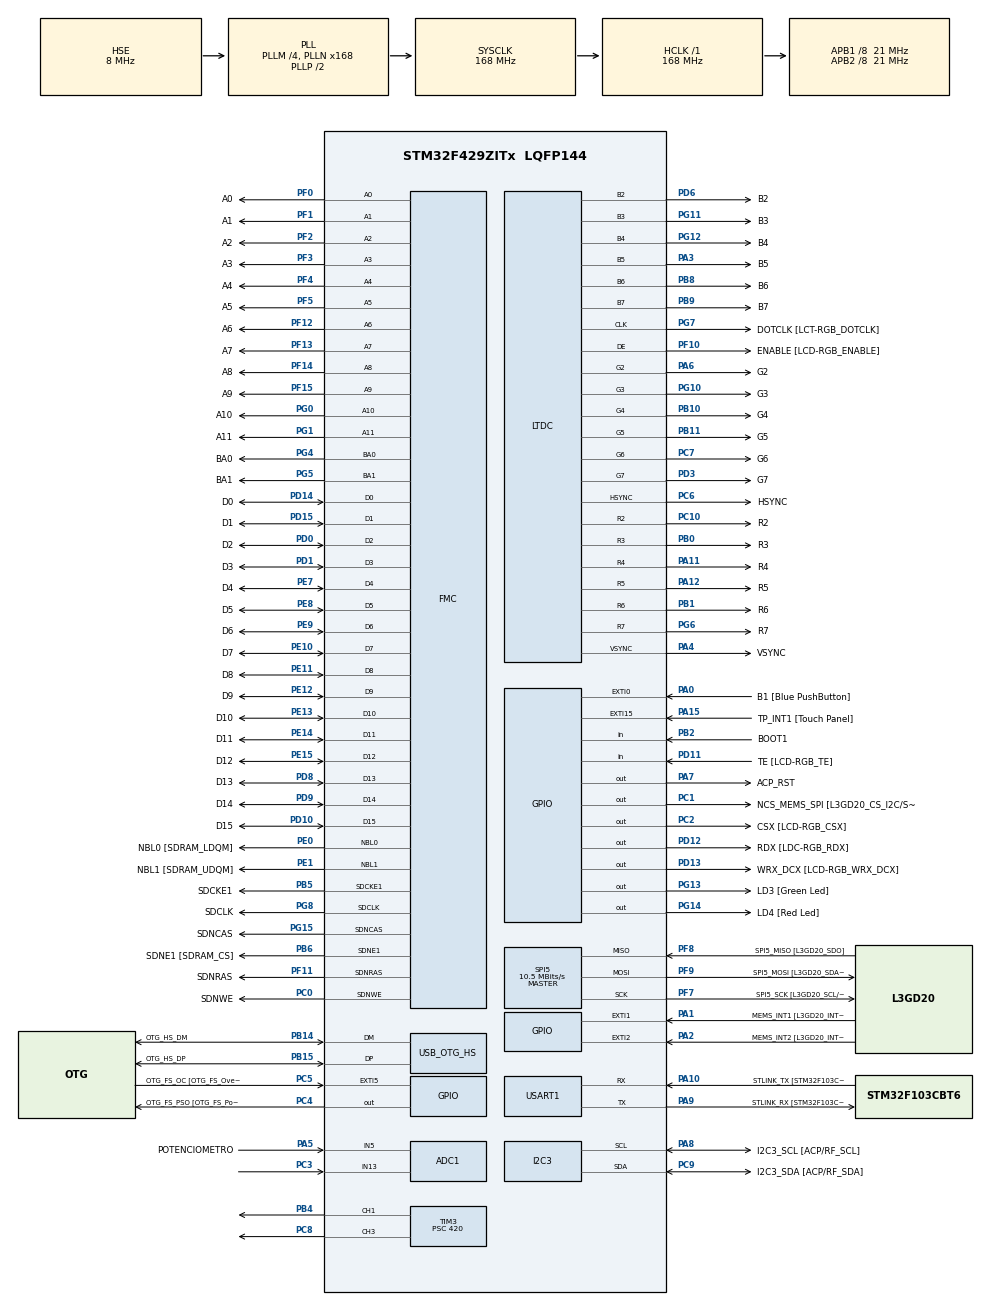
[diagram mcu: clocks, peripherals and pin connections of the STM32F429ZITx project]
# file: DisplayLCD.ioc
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ADC1.Channel-3\#ChannelRegularConversion=ADC_CHANNEL_5
ADC1.Channel-4\#ChannelRegularConversion=ADC_CHANNEL_5
ADC1.NbrOfConversion=2
ADC1.NbrOfConversionFlag=1
ADC1.Rank-3\#ChannelRegularConversion=1
ADC1.Rank-4\#ChannelRegularConversion=2
ADC1.SamplingTime-3\#ChannelRegularConversion=ADC_SAMPLETIME_144CYCLES
ADC1.SamplingTime-4\#ChannelRegularConversion=ADC_SAMPLETIME_144CYCLES
ADC1.ScanConvMode=ENABLE
ADC1.master=1
DMA2D.ColorMode=DMA2D_OUTPUT_RGB565
FATFS._MAX_SS=4096
LTDC.ActiveH=240
LTDC.ActiveW=320
Mcu.Family=STM32F4
Mcu.Name=STM32F429ZITx
Mcu.Package=LQFP144
NVIC.OTG_HS_IRQn=true\:0\:0\:false\:false\:true\:false
NVIC.PriorityGroup=NVIC_PRIORITYGROUP_0
NVIC.USART1_IRQn=true\:0\:0\:false\:false\:true\:true
PA0/WKUP.GPIO_Label=B1 [Blue PushButton]
PA0/WKUP.GPIO_ModeDefaultEXTI=GPIO_MODE_EVT_RISING
PA0/WKUP.GPIO_PuPd=GPIO_NOPULL
PA0/WKUP.Signal=GPXTI0
PA1.GPIO_Label=MEMS_INT1 [L3GD20_INT1]
PA1.GPIO_ModeDefaultEXTI=GPIO_MODE_EVT_RISING
PA1.GPIO_PuPd=GPIO_NOPULL
PA1.Signal=GPXTI1
PA10.GPIO_Label=STLINK_TX [STM32F103CBT6_PA2]
PA10.Mode=Asynchronous
PA10.Signal=USART1_RX
PA11.GPIO_Label=R4
PA11.GPIO_Mode=GPIO_MODE_AF_PP
PA11.GPIO_PuPd=GPIO_NOPULL
PA11.GPIO_Speed=GPIO_SPEED_FREQ_LOW
PA11.Mode=RGB666
PA11.Signal=LTDC_R4
PA12.GPIO_Label=R5
PA12.GPIO_Mode=GPIO_MODE_AF_PP
PA12.GPIO_PuPd=GPIO_NOPULL
PA12.GPIO_Speed=GPIO_SPEED_FREQ_LOW
PA12.Mode=RGB666
PA12.Signal=LTDC_R5
PA13.GPIO_Label=SWDIO
PA13.Mode=Serial_Wire
PA13.Signal=SYS_JTMS-SWDIO
PA14.GPIO_Label=SWCLK
PA14.Mode=Serial_Wire
PA14.Signal=SYS_JTCK-SWCLK
PA15.GPIO_Label=TP_INT1 [Touch Panel]
PA15.GPIO_ModeDefaultEXTI=GPIO_MODE_EVT_RISING
PA15.GPIO_PuPd=GPIO_NOPULL
PA15.Signal=GPXTI15
PA2.GPIO_Label=MEMS_INT2 [L3GD20_INT2]
PA2.GPIO_ModeDefaultEXTI=GPIO_MODE_EVT_RISING
PA2.GPIO_PuPd=GPIO_NOPULL
PA2.Signal=GPXTI2
PA3.GPIO_Label=B5
PA3.GPIO_Mode=GPIO_MODE_AF_PP
PA3.GPIO_PuPd=GPIO_NOPULL
PA3.GPIO_Speed=GPIO_SPEED_FREQ_LOW
PA3.Mode=RGB666
PA3.Signal=LTDC_B5
PA4.GPIO_Label=VSYNC
PA4.GPIO_Mode=GPIO_MODE_AF_PP
PA4.GPIO_PuPd=GPIO_NOPULL
PA4.GPIO_Speed=GPIO_SPEED_FREQ_LOW
PA4.Mode=RGB666
PA4.Signal=LTDC_VSYNC
PA5.GPIO_Label=POTENCIOMETRO
PA5.Signal=ADCx_IN5
PA6.GPIO_Label=G2
PA6.GPIO_Mode=GPIO_MODE_AF_PP
PA6.GPIO_PuPd=GPIO_NOPULL
PA6.GPIO_Speed=GPIO_SPEED_FREQ_LOW
PA6.Mode=RGB666
PA6.Signal=LTDC_G2
PA7.GPIO_Label=ACP_RST
PA7.GPIO_Mode=GPIO_MODE_OUTPUT_PP
PA7.GPIO_PuPd=GPIO_NOPULL
PA7.GPIO_Speed=GPIO_SPEED_FREQ_LOW
PA7.Signal=GPIO_Output
PA8.GPIO_Label=I2C3_SCL [ACP/RF_SCL]
PA8.GPIO_Mode=GPIO_MODE_AF_OD
PA8.GPIO_PuPd=GPIO_NOPULL
PA8.GPIO_Speed=GPIO_SPEED_FREQ_LOW
PA8.Mode=I2C
PA8.Signal=I2C3_SCL
PA9.GPIO_Label=STLINK_RX [STM32F103CBT6_PA3]
PA9.Mode=Asynchronous
PA9.Signal=USART1_TX
PB0.GPIO_Label=R3
PB0.GPIO_Mode=GPIO_MODE_AF_PP
PB0.GPIO_PuPd=GPIO_NOPULL
PB0.GPIO_Speed=GPIO_SPEED_FREQ_LOW
PB0.Mode=RGB666
PB0.Signal=LTDC_R3
PB1.GPIO_Label=R6
PB1.GPIO_Mode=GPIO_MODE_AF_PP
PB1.GPIO_PuPd=GPIO_NOPULL
PB1.GPIO_Speed=GPIO_SPEED_FREQ_LOW
PB1.Mode=RGB666
PB1.Signal=LTDC_R6
PB10.GPIO_Label=G4
PB10.GPIO_Mode=GPIO_MODE_AF_PP
PB10.GPIO_PuPd=GPIO_NOPULL
PB10.GPIO_Speed=GPIO_SPEED_FREQ_LOW
PB10.Mode=RGB666
PB10.Signal=LTDC_G4
PB11.GPIO_Label=G5
PB11.GPIO_Mode=GPIO_MODE_AF_PP
PB11.GPIO_PuPd=GPIO_NOPULL
PB11.GPIO_Speed=GPIO_SPEED_FREQ_LOW
PB11.Mode=RGB666
PB11.Signal=LTDC_G5
PB12.GPIO_Label=OTG_HS_ID
PB12.GPIO_Mode=GPIO_MODE_AF_PP
PB12.GPIO_PuPd=GPIO_NOPULL
PB12.GPIO_Speed=GPIO_SPEED_FREQ_LOW
PB12.Signal=USB_OTG_HS_ID
PB13.GPIO_Label=VBUS_HS
PB13.GPIO_Mode=GPIO_MODE_INPUT
PB13.GPIO_PuPd=GPIO_NOPULL
PB13.Signal=USB_OTG_HS_VBUS
PB14.GPIO_Label=OTG_HS_DM
PB14.GPIO_Mode=GPIO_MODE_AF_PP
PB14.GPIO_PuPd=GPIO_NOPULL
PB14.GPIO_Speed=GPIO_SPEED_FREQ_LOW
PB14.Mode=Host_FS
PB14.Signal=USB_OTG_HS_DM
PB15.GPIO_Label=OTG_HS_DP
PB15.GPIO_Mode=GPIO_MODE_AF_PP
PB15.GPIO_PuPd=GPIO_NOPULL
PB15.GPIO_Speed=GPIO_SPEED_FREQ_LOW
PB15.Mode=Host_FS
PB15.Signal=USB_OTG_HS_DP
PB2/BOOT1.GPIO_Label=BOOT1
PB2/BOOT1.GPIO_Mode=GPIO_MODE_INPUT
PB2/BOOT1.GPIO_PuPd=GPIO_NOPULL
PB2/BOOT1.Signal=GPIO_Input
PB4.Signal=S_TIM3_CH1
PB5.GPIO_Label=SDCKE1
PB5.GPIO_Mode=GPIO_MODE_AF_PP
PB5.GPIO_PuPd=GPIO_NOPULL
PB5.GPIO_Speed=GPIO_SPEED_FREQ_VERY_HIGH
PB5.Mode=SdramChipSelect2_1
PB5.Signal=FMC_SDCKE1
PB6.GPIO_Label=SDNE1 [SDRAM_CS]
PB6.GPIO_Mode=GPIO_MODE_AF_PP
PB6.GPIO_PuPd=GPIO_NOPULL
PB6.GPIO_Speed=GPIO_SPEED_FREQ_VERY_HIGH
PB6.Mode=SdramChipSelect2_1
PB6.Signal=FMC_SDNE1
PB8.GPIO_Label=B6
PB8.GPIO_Mode=GPIO_MODE_AF_PP
PB8.GPIO_PuPd=GPIO_NOPULL
PB8.GPIO_Speed=GPIO_SPEED_FREQ_LOW
PB8.Mode=RGB666
PB8.Signal=LTDC_B6
PB9.GPIO_Label=B7
PB9.GPIO_Mode=GPIO_MODE_AF_PP
PB9.GPIO_PuPd=GPIO_NOPULL
PB9.GPIO_Speed=GPIO_SPEED_FREQ_LOW
PB9.Mode=RGB666
PB9.Signal=LTDC_B7
PC0.GPIO_Label=SDNWE
PC0.GPIO_Mode=GPIO_MODE_AF_PP
PC0.GPIO_PuPd=GPIO_NOPULL
PC0.GPIO_Speed=GPIO_SPEED_FREQ_VERY_HIGH
PC0.Signal=FMC_SDNWE
PC1.GPIO_Label=NCS_MEMS_SPI [L3GD20_CS_I2C/SPI]
PC1.GPIO_Mode=GPIO_MODE_OUTPUT_PP
PC1.GPIO_PuPd=GPIO_NOPULL
PC1.GPIO_Speed=GPIO_SPEED_FREQ_LOW
PC1.Signal=GPIO_Output
PC10.GPIO_Label=R2
PC10.GPIO_Mode=GPIO_MODE_AF_PP
PC10.GPIO_PuPd=GPIO_NOPULL
PC10.GPIO_Speed=GPIO_SPEED_FREQ_LOW
PC10.Mode=RGB666
PC10.Signal=LTDC_R2
PC14/OSC32_IN.GPIO_Label=PC14-OSC32_IN
PC14/OSC32_IN.Signal=RCC_OSC32_IN
PC15/OSC32_OUT.GPIO_Label=PC15-OSC32_OUT
PC15/OSC32_OUT.Signal=RCC_OSC32_OUT
PC2.GPIO_Label=CSX [LCD-RGB_CSX]
PC2.GPIO_Mode=GPIO_MODE_OUTPUT_PP
PC2.GPIO_PuPd=GPIO_NOPULL
PC2.GPIO_Speed=GPIO_SPEED_FREQ_LOW
PC2.Signal=GPIO_Output
PC3.Signal=ADCx_IN13
PC4.GPIO_Label=OTG_FS_PSO [OTG_FS_PowerSwitchOn]
PC4.GPIO_Mode=GPIO_MODE_OUTPUT_PP
PC4.GPIO_PuPd=GPIO_NOPULL
PC4.GPIO_Speed=GPIO_SPEED_FREQ_LOW
PC4.Signal=GPIO_Output
PC5.GPIO_Label=OTG_FS_OC [OTG_FS_OverCurrent]
PC5.GPIO_ModeDefaultEXTI=GPIO_MODE_EVT_RISING
PC5.Signal=GPXTI5
PC6.GPIO_Label=HSYNC
PC6.GPIO_Mode=GPIO_MODE_AF_PP
PC6.GPIO_PuPd=GPIO_NOPULL
PC6.GPIO_Speed=GPIO_SPEED_FREQ_LOW
PC6.Mode=RGB666
PC6.Signal=LTDC_HSYNC
PC7.GPIO_Label=G6
PC7.GPIO_Mode=GPIO_MODE_AF_PP
PC7.GPIO_PuPd=GPIO_NOPULL
PC7.GPIO_Speed=GPIO_SPEED_FREQ_LOW
PC7.Mode=RGB666
PC7.Signal=LTDC_G6
PC8.Signal=S_TIM3_CH3
PC9.GPIO_Label=I2C3_SDA [ACP/RF_SDA]
PC9.GPIO_Mode=GPIO_MODE_AF_OD
PC9.GPIO_PuPd=GPIO_NOPULL
PC9.GPIO_Speed=GPIO_SPEED_FREQ_LOW
PC9.Mode=I2C
PC9.Signal=I2C3_SDA
PD0.GPIO_Label=D2
PD0.GPIO_Mode=GPIO_MODE_AF_PP
PD0.GPIO_PuPd=GPIO_NOPULL
PD0.GPIO_Speed=GPIO_SPEED_FREQ_VERY_HIGH
PD0.Signal=FMC_D2_DA2
PD1.GPIO_Label=D3
PD1.GPIO_Mode=GPIO_MODE_AF_PP
PD1.GPIO_PuPd=GPIO_NOPULL
PD1.GPIO_Speed=GPIO_SPEED_FREQ_VERY_HIGH
PD1.Signal=FMC_D3_DA3
PD10.GPIO_Label=D15
PD10.GPIO_Mode=GPIO_MODE_AF_PP
PD10.GPIO_PuPd=GPIO_NOPULL
PD10.GPIO_Speed=GPIO_SPEED_FREQ_VERY_HIGH
PD10.Signal=FMC_D15_DA15
PD11.GPIO_Label=TE [LCD-RGB_TE]
PD11.GPIO_Mode=GPIO_MODE_INPUT
PD11.GPIO_PuPd=GPIO_NOPULL
PD11.Signal=GPIO_Input
PD12.GPIO_Label=RDX [LDC-RGB_RDX]
PD12.GPIO_Mode=GPIO_MODE_OUTPUT_PP
PD12.GPIO_PuPd=GPIO_NOPULL
PD12.GPIO_Speed=GPIO_SPEED_FREQ_LOW
PD12.Signal=GPIO_Output
PD13.GPIO_Label=WRX_DCX [LCD-RGB_WRX_DCX]
PD13.GPIO_Mode=GPIO_MODE_OUTPUT_PP
PD13.GPIO_PuPd=GPIO_NOPULL
PD13.GPIO_Speed=GPIO_SPEED_FREQ_LOW
PD13.Signal=GPIO_Output
PD14.GPIO_Label=D0
PD14.GPIO_Mode=GPIO_MODE_AF_PP
PD14.GPIO_PuPd=GPIO_NOPULL
PD14.GPIO_Speed=GPIO_SPEED_FREQ_VERY_HIGH
PD14.Signal=FMC_D0_DA0
PD15.GPIO_Label=D1
PD15.GPIO_Mode=GPIO_MODE_AF_PP
PD15.GPIO_PuPd=GPIO_NOPULL
PD15.GPIO_Speed=GPIO_SPEED_FREQ_VERY_HIGH
PD15.Signal=FMC_D1_DA1
PD3.GPIO_Label=G7
PD3.GPIO_Mode=GPIO_MODE_AF_PP
PD3.GPIO_PuPd=GPIO_NOPULL
PD3.GPIO_Speed=GPIO_SPEED_FREQ_LOW
PD3.Mode=RGB666
PD3.Signal=LTDC_G7
PD6.GPIO_Label=B2
PD6.GPIO_Mode=GPIO_MODE_AF_PP
PD6.GPIO_PuPd=GPIO_NOPULL
PD6.GPIO_Speed=GPIO_SPEED_FREQ_LOW
PD6.Mode=RGB666
PD6.Signal=LTDC_B2
PD8.GPIO_Label=D13
PD8.GPIO_Mode=GPIO_MODE_AF_PP
PD8.GPIO_PuPd=GPIO_NOPULL
PD8.GPIO_Speed=GPIO_SPEED_FREQ_VERY_HIGH
PD8.Signal=FMC_D13_DA13
PD9.GPIO_Label=D14
PD9.GPIO_Mode=GPIO_MODE_AF_PP
PD9.GPIO_PuPd=GPIO_NOPULL
PD9.GPIO_Speed=GPIO_SPEED_FREQ_VERY_HIGH
PD9.Signal=FMC_D14_DA14
PE0.GPIO_Label=NBL0 [SDRAM_LDQM]
PE0.GPIO_Mode=GPIO_MODE_AF_PP
PE0.GPIO_PuPd=GPIO_NOPULL
PE0.GPIO_Speed=GPIO_SPEED_FREQ_VERY_HIGH
PE0.Signal=FMC_NBL0
PE1.GPIO_Label=NBL1 [SDRAM_UDQM]
PE1.GPIO_Mode=GPIO_MODE_AF_PP
PE1.GPIO_PuPd=GPIO_NOPULL
PE1.GPIO_Speed=GPIO_SPEED_FREQ_VERY_HIGH
PE1.Signal=FMC_NBL1
PE10.GPIO_Label=D7
PE10.GPIO_Mode=GPIO_MODE_AF_PP
PE10.GPIO_PuPd=GPIO_NOPULL
PE10.GPIO_Speed=GPIO_SPEED_FREQ_VERY_HIGH
PE10.Signal=FMC_D7_DA7
PE11.GPIO_Label=D8
PE11.GPIO_Mode=GPIO_MODE_AF_PP
PE11.GPIO_PuPd=GPIO_NOPULL
PE11.GPIO_Speed=GPIO_SPEED_FREQ_VERY_HIGH
PE11.Signal=FMC_D8_DA8
PE12.GPIO_Label=D9
PE12.GPIO_Mode=GPIO_MODE_AF_PP
PE12.GPIO_PuPd=GPIO_NOPULL
PE12.GPIO_Speed=GPIO_SPEED_FREQ_VERY_HIGH
PE12.Signal=FMC_D9_DA9
PE13.GPIO_Label=D10
PE13.GPIO_Mode=GPIO_MODE_AF_PP
PE13.GPIO_PuPd=GPIO_NOPULL
PE13.GPIO_Speed=GPIO_SPEED_FREQ_VERY_HIGH
PE13.Signal=FMC_D10_DA10
PE14.GPIO_Label=D11
PE14.GPIO_Mode=GPIO_MODE_AF_PP
PE14.GPIO_PuPd=GPIO_NOPULL
PE14.GPIO_Speed=GPIO_SPEED_FREQ_VERY_HIGH
PE14.Signal=FMC_D11_DA11
PE15.GPIO_Label=D12
PE15.GPIO_Mode=GPIO_MODE_AF_PP
PE15.GPIO_PuPd=GPIO_NOPULL
PE15.GPIO_Speed=GPIO_SPEED_FREQ_VERY_HIGH
PE15.Signal=FMC_D12_DA12
PE7.GPIO_Label=D4
PE7.GPIO_Mode=GPIO_MODE_AF_PP
PE7.GPIO_PuPd=GPIO_NOPULL
PE7.GPIO_Speed=GPIO_SPEED_FREQ_VERY_HIGH
PE7.Signal=FMC_D4_DA4
PE8.GPIO_Label=D5
PE8.GPIO_Mode=GPIO_MODE_AF_PP
PE8.GPIO_PuPd=GPIO_NOPULL
PE8.GPIO_Speed=GPIO_SPEED_FREQ_VERY_HIGH
PE8.Signal=FMC_D5_DA5
PE9.GPIO_Label=D6
PE9.GPIO_Mode=GPIO_MODE_AF_PP
PE9.GPIO_PuPd=GPIO_NOPULL
PE9.GPIO_Speed=GPIO_SPEED_FREQ_VERY_HIGH
PE9.Signal=FMC_D6_DA6
PF0.GPIO_Label=A0
PF0.GPIO_Mode=GPIO_MODE_AF_PP
PF0.GPIO_PuPd=GPIO_NOPULL
PF0.GPIO_Speed=GPIO_SPEED_FREQ_VERY_HIGH
PF0.Signal=FMC_A0
PF1.GPIO_Label=A1
PF1.GPIO_Mode=GPIO_MODE_AF_PP
PF1.GPIO_PuPd=GPIO_NOPULL
PF1.GPIO_Speed=GPIO_SPEED_FREQ_VERY_HIGH
PF1.Signal=FMC_A1
PF10.GPIO_Label=ENABLE [LCD-RGB_ENABLE]
PF10.GPIO_Mode=GPIO_MODE_AF_PP
PF10.GPIO_PuPd=GPIO_NOPULL
PF10.GPIO_Speed=GPIO_SPEED_FREQ_LOW
PF10.Mode=RGB666
PF10.Signal=LTDC_DE
PF11.GPIO_Label=SDNRAS
PF11.GPIO_Mode=GPIO_MODE_AF_PP
PF11.GPIO_PuPd=GPIO_NOPULL
PF11.GPIO_Speed=GPIO_SPEED_FREQ_VERY_HIGH
PF11.Signal=FMC_SDNRAS
PF12.GPIO_Label=A6
PF12.GPIO_Mode=GPIO_MODE_AF_PP
PF12.GPIO_PuPd=GPIO_NOPULL
PF12.GPIO_Speed=GPIO_SPEED_FREQ_VERY_HIGH
PF12.Signal=FMC_A6
PF13.GPIO_Label=A7
PF13.GPIO_Mode=GPIO_MODE_AF_PP
PF13.GPIO_PuPd=GPIO_NOPULL
PF13.GPIO_Speed=GPIO_SPEED_FREQ_VERY_HIGH
PF13.Signal=FMC_A7
PF14.GPIO_Label=A8
PF14.GPIO_Mode=GPIO_MODE_AF_PP
PF14.GPIO_PuPd=GPIO_NOPULL
PF14.GPIO_Speed=GPIO_SPEED_FREQ_VERY_HIGH
PF14.Signal=FMC_A8
PF15.GPIO_Label=A9
PF15.GPIO_Mode=GPIO_MODE_AF_PP
PF15.GPIO_PuPd=GPIO_NOPULL
PF15.GPIO_Speed=GPIO_SPEED_FREQ_VERY_HIGH
PF15.Signal=FMC_A9
PF2.GPIO_Label=A2
PF2.GPIO_Mode=GPIO_MODE_AF_PP
PF2.GPIO_PuPd=GPIO_NOPULL
PF2.GPIO_Speed=GPIO_SPEED_FREQ_VERY_HIGH
PF2.Signal=FMC_A2
PF3.GPIO_Label=A3
PF3.GPIO_Mode=GPIO_MODE_AF_PP
PF3.GPIO_PuPd=GPIO_NOPULL
PF3.GPIO_Speed=GPIO_SPEED_FREQ_VERY_HIGH
PF3.Signal=FMC_A3
PF4.GPIO_Label=A4
PF4.GPIO_Mode=GPIO_MODE_AF_PP
PF4.GPIO_PuPd=GPIO_NOPULL
PF4.GPIO_Speed=GPIO_SPEED_FREQ_VERY_HIGH
PF4.Signal=FMC_A4
PF5.GPIO_Label=A5
PF5.GPIO_Mode=GPIO_MODE_AF_PP
PF5.GPIO_PuPd=GPIO_NOPULL
PF5.GPIO_Speed=GPIO_SPEED_FREQ_VERY_HIGH
PF5.Signal=FMC_A5
PF7.GPIO_Label=SPI5_SCK [L3GD20_SCL/SPC]
PF7.GPIO_Mode=GPIO_MODE_AF_PP
PF7.GPIO_PuPd=GPIO_NOPULL
PF7.GPIO_Speed=GPIO_SPEED_FREQ_LOW
PF7.Mode=Full_Duplex_Master
PF7.Signal=SPI5_SCK
PF8.GPIO_Label=SPI5_MISO [L3GD20_SDO]
PF8.GPIO_Mode=GPIO_MODE_AF_PP
PF8.GPIO_PuPd=GPIO_NOPULL
PF8.GPIO_Speed=GPIO_SPEED_FREQ_LOW
PF8.Mode=Full_Duplex_Master
PF8.Signal=SPI5_MISO
PF9.GPIO_Label=SPI5_MOSI [L3GD20_SDA/SDI/SDO]
PF9.GPIO_Mode=GPIO_MODE_AF_PP
PF9.GPIO_PuPd=GPIO_NOPULL
PF9.GPIO_Speed=GPIO_SPEED_FREQ_LOW
PF9.Mode=Full_Duplex_Master
PF9.Signal=SPI5_MOSI
PG0.GPIO_Label=A10
PG0.GPIO_Mode=GPIO_MODE_AF_PP
PG0.GPIO_PuPd=GPIO_NOPULL
PG0.GPIO_Speed=GPIO_SPEED_FREQ_VERY_HIGH
PG0.Signal=FMC_A10
PG1.GPIO_Label=A11
PG1.GPIO_Mode=GPIO_MODE_AF_PP
PG1.GPIO_PuPd=GPIO_NOPULL
PG1.GPIO_Speed=GPIO_SPEED_FREQ_VERY_HIGH
PG1.Signal=FMC_A11
PG10.GPIO_Label=G3
PG10.GPIO_Mode=GPIO_MODE_AF_PP
PG10.GPIO_PuPd=GPIO_NOPULL
PG10.GPIO_Speed=GPIO_SPEED_FREQ_LOW
PG10.Mode=RGB666
PG10.Signal=LTDC_G3
PG11.GPIO_Label=B3
PG11.GPIO_Mode=GPIO_MODE_AF_PP
PG11.GPIO_PuPd=GPIO_NOPULL
PG11.GPIO_Speed=GPIO_SPEED_FREQ_LOW
PG11.Mode=RGB666
PG11.Signal=LTDC_B3
PG12.GPIO_Label=B4
PG12.GPIO_Mode=GPIO_MODE_AF_PP
PG12.GPIO_PuPd=GPIO_NOPULL
PG12.GPIO_Speed=GPIO_SPEED_FREQ_LOW
PG12.Mode=RGB666
PG12.Signal=LTDC_B4
PG13.GPIO_Label=LD3 [Green Led]
PG13.GPIO_Mode=GPIO_MODE_OUTPUT_PP
PG13.GPIO_PuPd=GPIO_NOPULL
PG13.GPIO_Speed=GPIO_SPEED_FREQ_LOW
PG13.Signal=GPIO_Output
PG14.GPIO_Label=LD4 [Red Led]
PG14.GPIO_Mode=GPIO_MODE_OUTPUT_PP
PG14.GPIO_PuPd=GPIO_NOPULL
PG14.GPIO_Speed=GPIO_SPEED_FREQ_LOW
PG14.Signal=GPIO_Output
PG15.GPIO_Label=SDNCAS
PG15.GPIO_Mode=GPIO_MODE_AF_PP
PG15.GPIO_PuPd=GPIO_NOPULL
PG15.GPIO_Speed=GPIO_SPEED_FREQ_VERY_HIGH
PG15.Signal=FMC_SDNCAS
PG4.GPIO_Label=BA0
PG4.GPIO_Mode=GPIO_MODE_AF_PP
PG4.GPIO_PuPd=GPIO_NOPULL
PG4.GPIO_Speed=GPIO_SPEED_FREQ_VERY_HIGH
PG4.Signal=FMC_A14_BA0
PG5.GPIO_Label=BA1
PG5.GPIO_Mode=GPIO_MODE_AF_PP
PG5.GPIO_PuPd=GPIO_NOPULL
PG5.GPIO_Speed=GPIO_SPEED_FREQ_VERY_HIGH
PG5.Signal=FMC_A15_BA1
PG6.GPIO_Label=R7
PG6.GPIO_Mode=GPIO_MODE_AF_PP
PG6.GPIO_PuPd=GPIO_NOPULL
PG6.GPIO_Speed=GPIO_SPEED_FREQ_LOW
PG6.Mode=RGB666
PG6.Signal=LTDC_R7
PG7.GPIO_Label=DOTCLK [LCT-RGB_DOTCLK]
PG7.GPIO_Mode=GPIO_MODE_AF_PP
PG7.GPIO_PuPd=GPIO_NOPULL
PG7.GPIO_Speed=GPIO_SPEED_FREQ_LOW
PG7.Mode=RGB666
PG7.Signal=LTDC_CLK
PG8.GPIO_Label=SDCLK
PG8.GPIO_Mode=GPIO_MODE_AF_PP
PG8.GPIO_PuPd=GPIO_NOPULL
PG8.GPIO_Speed=GPIO_SPEED_FREQ_VERY_HIGH
PG8.Signal=FMC_SDCLK
PH0/OSC_IN.GPIO_Label=PH0-OSC_IN
PH0/OSC_IN.Mode=HSE-External-Oscillator
PH0/OSC_IN.Signal=RCC_OSC_IN
PH1/OSC_OUT.GPIO_Label=PH1-OSC_OUT
PH1/OSC_OUT.Mode=HSE-External-Oscillator
PH1/OSC_OUT.Signal=RCC_OSC_OUT
ProjectManager.HeapSize=0x200
ProjectManager.StackSize=0x400
ProjectManager.TargetToolchain=MDK-ARM V5
RCC.48MHZClocksFreq_Value=48000000
RCC.AHBFreq_Value=168000000
RCC.APB1CLKDivider=RCC_HCLK_DIV8
RCC.APB1Freq_Value=21000000
RCC.APB1TimFreq_Value=42000000
RCC.APB2CLKDivider=RCC_HCLK_DIV8
RCC.APB2Freq_Value=21000000
RCC.APB2TimFreq_Value=42000000
RCC.CortexFreq_Value=168000000
RCC.HCLKFreq_Value=168000000
RCC.HSE_VALUE=8000000
RCC.HSI_VALUE=16000000
RCC.LSE_VALUE=32768
RCC.PLLM=4
RCC.PLLN=168
RCC.PLLQ=7
RCC.PLLSAIN=216
RCC.SYSCLKFreq_VALUE=168000000
RCC.SYSCLKSource=RCC_SYSCLKSOURCE_PLLCLK
RCC.VCOOutputFreq_Value=336000000
RTC.Format=RTC_FORMAT_BIN
SH.ADCx_IN13.0=ADC1_IN13,IN13
SH.ADCx_IN5.0=ADC1_IN5,IN5
SH.FMC_A0.0=FMC_A0,12b-sda1
SH.FMC_A1.0=FMC_A1,12b-sda1
SH.FMC_A10.0=FMC_A10,12b-sda1
SH.FMC_A11.0=FMC_A11,12b-sda1
SH.FMC_A14_BA0.0=FMC_BA0,FourSdramBanks1
SH.FMC_A15_BA1.0=FMC_BA1,FourSdramBanks1
SH.FMC_A2.0=FMC_A2,12b-sda1
SH.FMC_A3.0=FMC_A3,12b-sda1
SH.FMC_A4.0=FMC_A4,12b-sda1
SH.FMC_A5.0=FMC_A5,12b-sda1
SH.FMC_A6.0=FMC_A6,12b-sda1
SH.FMC_A7.0=FMC_A7,12b-sda1
SH.FMC_A8.0=FMC_A8,12b-sda1
SH.FMC_A9.0=FMC_A9,12b-sda1
SH.FMC_D0_DA0.0=FMC_D0,sd-16b-d1
SH.FMC_D10_DA10.0=FMC_D10,sd-16b-d1
SH.FMC_D11_DA11.0=FMC_D11,sd-16b-d1
SH.FMC_D12_DA12.0=FMC_D12,sd-16b-d1
SH.FMC_D13_DA13.0=FMC_D13,sd-16b-d1
SH.FMC_D14_DA14.0=FMC_D14,sd-16b-d1
SH.FMC_D15_DA15.0=FMC_D15,sd-16b-d1
SH.FMC_D1_DA1.0=FMC_D1,sd-16b-d1
SH.FMC_D2_DA2.0=FMC_D2,sd-16b-d1
SH.FMC_D3_DA3.0=FMC_D3,sd-16b-d1
SH.FMC_D4_DA4.0=FMC_D4,sd-16b-d1
SH.FMC_D5_DA5.0=FMC_D5,sd-16b-d1
SH.FMC_D6_DA6.0=FMC_D6,sd-16b-d1
SH.FMC_D7_DA7.0=FMC_D7,sd-16b-d1
SH.FMC_D8_DA8.0=FMC_D8,sd-16b-d1
SH.FMC_D9_DA9.0=FMC_D9,sd-16b-d1
SH.FMC_NBL0.0=FMC_NBL0,Sd2ByteEnable1
SH.FMC_NBL1.0=FMC_NBL1,Sd2ByteEnable1
SH.FMC_SDCLK.0=FMC_SDCLK,12b-sda1
SH.FMC_SDNCAS.0=FMC_SDNCAS,12b-sda1
SH.FMC_SDNRAS.0=FMC_SDNRAS,12b-sda1
SH.FMC_SDNWE.0=FMC_SDNWE,12b-sda1
SH.S_TIM3_CH1.0=TIM3_CH1,PWM Generation1 CH1
SH.S_TIM3_CH3.0=TIM3_CH3,PWM Generation3 CH3
SPI5.CalculateBaudRate=10.5 MBits/s
SPI5.Direction=SPI_DIRECTION_2LINES
SPI5.Mode=SPI_MODE_MASTER
SPI5.VirtualType=VM_MASTER
TIM2.Prescaler=420
TIM3.Channel-PWM\ Generation1\ CH1=TIM_CHANNEL_1
TIM3.Channel-PWM\ Generation3\ CH3=TIM_CHANNEL_3
TIM3.Period=99
TIM3.Prescaler=420
USART1.VirtualMode=VM_ASYNC
USB_HOST.BSP.number=1
USB_HOST.USBH_HandleTypeDef-MSC_HS=hUsbHostHS
USB_HOST.VirtualModeHS=Msc
USB_HOST0.BSP.STBoard=false
USB_HOST0.BSP.api=Unknown
USB_HOST0.BSP.i2caddr=0
USB_HOST0.BSP.instance=PC4
USB_HOST0.BSP.ip=GPIO
USB_HOST0.BSP.mode=Output
USB_HOST0.BSP.name=Drive_VBUS_HS
USB_HOST0.BSP.solution=PC4
USB_OTG_HS.VirtualMode-Host_FS=Host_FS
VP_DMA2D_VS_DMA2D.Mode=DMA2D_Activate
VP_FATFS_VS_USB.Mode=USB
VP_RTC_VS_RTC_Activate.Mode=RTC_Enabled
VP_RTC_VS_RTC_Calendar.Mode=RTC_Calendar
VP_TIM2_VS_ClockSourceINT.Mode=Internal
VP_TIM3_VS_ClockSourceINT.Mode=Internal
VP_USB_HOST_VS_USB_HOST_MSC_HS.Mode=MSC_HS
board=32F429IDISCOVERY

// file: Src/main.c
/* USER CODE BEGIN Header */
/* USER CODE END Header */

#include "main.h"
#include "adc.h"
#include "dma2d.h"
#include "fatfs.h"
#include "i2c.h"
#include "ltdc.h"
#include "rtc.h"
#include "spi.h"
#include "tim.h"
#include "usart.h"
#include "usb_host.h"
#include "gpio.h"
#include "fmc.h"

/* USER CODE BEGIN Includes */
#include "stm32f429i_discovery_lcd.h"
#include "stm32f429i_discovery_sdram.h"
#include "stm32f429i_discovery_ts.h"
#include "string.h"
/* USER CODE END Includes */

void SystemClock_Config(void);
void MX_USB_HOST_Process(void);

/* USER CODE BEGIN 0 */

struct Control{

  RTC_TimeTypeDef sTime;
	RTC_DateTypeDef sDate;

  uint8_t dadoRX[30];

  float temperatura, umidade, pressao, corrente;
  int potenciometro, X;

	int indice;

  uint8_t vetor_print[30];

	int8_t estado_atual;
	int8_t estado_anterior;

}c;

struct PenDriveControl{
	FIL fp; //file handle
	FATFS fatfs; //structure with file system information
	char* text[100]; //text which will be written into file
	char filename[100];
	char buffer[200]; //buffer for data read from file
	uint32_t ret; //return variable
}p;

extern ApplicationTypeDef Appli_state;

void HAL_UART_RxCpltCallback(UART_HandleTypeDef *huart);
float le_umidade(void);
float le_temperatura(void);
float le_pressao(void);
float le_corrente(void);
void inicializa_vetor_uint8(uint8_t vetor[], int tam);
void leitura_AD(int tempo);
void aciona_PWM(void);
void renderiza_RTC(void);
void renderiza_sensores(void);
void configura_hora(void);
void inicializa_display(void);
void pendrive(void);
void monta_pendrive(void);

/* USER CODE END 0 */

int main(void)
{
  /* USER CODE BEGIN 1 */

	c.umidade = 0;
  c.corrente = 0;
  c.pressao = 0;
  c.temperatura = 0;
  c.potenciometro = 0;
	c.indice = 0;

  inicializa_vetor_uint8(c.dadoRX, 30);
  inicializa_vetor_uint8(c.vetor_print, 30);

  c.sTime.Hours = 18;
  c.sTime.Minutes = 30;
  c.sTime.Seconds = 0;

	c.sDate.Year = 70;
	c.sDate.Month = 01;
	c.sDate.Date = 01;

	c.estado_anterior = -1;
	c.estado_atual = -1;

	strcpy(p.filename,"log.csv");

  /* USER CODE END 1 */

  /* MCU Configuration--------------------------------------------------------*/

  /* Reset of all peripherals, Initializes the Flash interface and the Systick. */
  HAL_Init();

  /* Configure the system clock */
  SystemClock_Config();

  /* Initialize all configured peripherals */
  MX_GPIO_Init();
  MX_DMA2D_Init();
  MX_I2C3_Init();
  MX_LTDC_Init();
  MX_SPI5_Init();
  MX_FMC_Init();
  MX_USART1_UART_Init();
  MX_RTC_Init();
  MX_ADC1_Init();
  MX_TIM2_Init();
  MX_TIM3_Init();
  MX_USB_HOST_Init();
  MX_FATFS_Init();
  /* USER CODE BEGIN 2 */

  inicializa_display();

	// seta primeira hora e data RTC
	HAL_RTC_SetDate(&hrtc, &c.sDate, FORMAT_BIN);
  HAL_RTC_SetTime(&hrtc, &c.sTime, FORMAT_BIN);

	// armando primeira interrupcao
	HAL_UART_Receive_IT(&huart1,c.dadoRX,17);

	// inicializando PWM
	HAL_TIM_PWM_Start(&htim3,TIM_CHANNEL_3);
	HAL_TIM_PWM_Start(&htim3,TIM_CHANNEL_1);

	monta_pendrive();

  /* USER CODE END 2 */

  /* Infinite loop */
  while (1)
  {
    MX_USB_HOST_Process();

    /* USER CODE BEGIN 3 */

	  aciona_PWM();
		renderiza_RTC();
		leitura_AD(200);
		renderiza_sensores();

		HAL_Delay(800);
		MX_USB_HOST_Process();
		pendrive();

  }
  /* USER CODE END 3 */
}

void SystemClock_Config(void)
{
  RCC_OscInitTypeDef RCC_OscInitStruct = {0};
  RCC_ClkInitTypeDef RCC_ClkInitStruct = {0};
  RCC_PeriphCLKInitTypeDef PeriphClkInitStruct = {0};

  /**Configure the main internal regulator output voltage
  */
  __HAL_RCC_PWR_CLK_ENABLE();
  __HAL_PWR_VOLTAGESCALING_CONFIG(PWR_REGULATOR_VOLTAGE_SCALE1);
  /**Initializes the CPU, AHB and APB busses clocks
  */
  RCC_OscInitStruct.OscillatorType = RCC_OSCILLATORTYPE_LSI|RCC_OSCILLATORTYPE_HSE;
  RCC_OscInitStruct.HSEState = RCC_HSE_ON;
  RCC_OscInitStruct.LSIState = RCC_LSI_ON;
  RCC_OscInitStruct.PLL.PLLState = RCC_PLL_ON;
  RCC_OscInitStruct.PLL.PLLSource = RCC_PLLSOURCE_HSE;
  RCC_OscInitStruct.PLL.PLLM = 4;
  RCC_OscInitStruct.PLL.PLLN = 168;
  RCC_OscInitStruct.PLL.PLLP = RCC_PLLP_DIV2;
  RCC_OscInitStruct.PLL.PLLQ = 7;
  if (HAL_RCC_OscConfig(&RCC_OscInitStruct) != HAL_OK)
  {
    Error_Handler();
  }
  /**Initializes the CPU, AHB and APB busses clocks
  */
  RCC_ClkInitStruct.ClockType = RCC_CLOCKTYPE_HCLK|RCC_CLOCKTYPE_SYSCLK
                              |RCC_CLOCKTYPE_PCLK1|RCC_CLOCKTYPE_PCLK2;
  RCC_ClkInitStruct.SYSCLKSource = RCC_SYSCLKSOURCE_PLLCLK;
  RCC_ClkInitStruct.AHBCLKDivider = RCC_SYSCLK_DIV1;
  RCC_ClkInitStruct.APB1CLKDivider = RCC_HCLK_DIV8;
  RCC_ClkInitStruct.APB2CLKDivider = RCC_HCLK_DIV8;

  if (HAL_RCC_ClockConfig(&RCC_ClkInitStruct, FLASH_LATENCY_5) != HAL_OK)
  {
    Error_Handler();
  }
  PeriphClkInitStruct.PeriphClockSelection = RCC_PERIPHCLK_LTDC|RCC_PERIPHCLK_RTC;
  PeriphClkInitStruct.PLLSAI.PLLSAIN = 216;
  PeriphClkInitStruct.PLLSAI.PLLSAIR = 2;
  PeriphClkInitStruct.PLLSAIDivR = RCC_PLLSAIDIVR_2;
  PeriphClkInitStruct.RTCClockSelection = RCC_RTCCLKSOURCE_LSI;
  if (HAL_RCCEx_PeriphCLKConfig(&PeriphClkInitStruct) != HAL_OK)
  {
    Error_Handler();
  }
}

/* USER CODE BEGIN 4 */

void HAL_UART_RxCpltCallback(UART_HandleTypeDef *huart)
{
	configura_hora();
	HAL_UART_Receive_IT(&huart1,c.dadoRX,17);
}
float le_umidade(void)
{
	uint8_t dado[2];
	dado[0] = 0x82;
	dado[1] = 0;

	uint16_t H0_rH_x2, H1_rH_x2;

	int16_t H0_T0_OUT, H1_T0_OUT;

	int16_t H_OUT;

	//escrever na memoria do sensor pra dar WAKE UP
	HAL_I2C_Mem_Write(&hi2c3,0xBE,0x20,I2C_MEMADD_SIZE_8BIT,&dado[0],1,50);

	//agora seguir roteiro

	//1 leitura dos registradores das posicoes 0x30 e 0x31
	HAL_I2C_Mem_Read(&hi2c3,0xBF,0x30,I2C_MEMADD_SIZE_8BIT,&dado[0],1,50);
	HAL_I2C_Mem_Read(&hi2c3,0xBF,0x31,I2C_MEMADD_SIZE_8BIT,&dado[1],1,50);

	H0_rH_x2 = dado[0]/2;
	H1_rH_x2 = dado[1]/2;

	float h = 0;

	//3 leitura dos 0x36, 0x37
	HAL_I2C_Mem_Read(&hi2c3,0xBF,0x36,I2C_MEMADD_SIZE_8BIT,&dado[0],1,50);
	HAL_I2C_Mem_Read(&hi2c3,0xBF,0x37,I2C_MEMADD_SIZE_8BIT,&dado[1],1,50);

	H0_T0_OUT = (dado[1] << 8) + dado[0];

	//4 leitura 0x3a, 0x3b
	HAL_I2C_Mem_Read(&hi2c3,0xBF,0x3a,I2C_MEMADD_SIZE_8BIT,&dado[0],1,50);
	HAL_I2C_Mem_Read(&hi2c3,0xBF,0x3b,I2C_MEMADD_SIZE_8BIT,&dado[1],1,50);

	H1_T0_OUT = (dado[1] << 8) + dado[0];

	// 5 leitura do 0x28 e 0x29
	HAL_I2C_Mem_Read(&hi2c3,0xBF,0x28,I2C_MEMADD_SIZE_8BIT,&dado[0],1,50);
	HAL_I2C_Mem_Read(&hi2c3,0xBF,0x29,I2C_MEMADD_SIZE_8BIT,&dado[1],1,50);

	H_OUT = (dado[1] << 8) + dado[0];

	// 6 calcular

	h = (((H1_rH_x2 - H0_rH_x2) * (H_OUT - H0_T0_OUT))/(H1_T0_OUT - H0_T0_OUT))+H0_rH_x2;

	return h;
}

float le_temperatura(void)
{
	uint8_t dado[2];
	uint16_t T0_degC = 0, T1_degC = 0;
	int16_t  T1_out = 0, T0_out = 0,T_out= 0;

	dado[0] = 0x82;
	HAL_I2C_Mem_Write(&hi2c3,0xBE,0x20,I2C_MEMADD_SIZE_8BIT,&dado[0],1,50);

	HAL_I2C_Mem_Read(&hi2c3,0xBF,0x32,I2C_MEMADD_SIZE_8BIT,&dado[0],1,50);
	HAL_I2C_Mem_Read(&hi2c3,0xBF,0x33,I2C_MEMADD_SIZE_8BIT,&dado[1],1,50);

	T0_degC = dado[0];
	T1_degC = dado[1];

	HAL_I2C_Mem_Read(&hi2c3,0xBF,0x35,I2C_MEMADD_SIZE_8BIT,&dado[0],1,50);

	T1_degC = ((dado[0] & 0xC) << 6) + T1_degC;
	T0_degC = ((dado[0]  & 3) << 8) + T0_degC;
	T0_degC = T0_degC /8;
	T1_degC = T1_degC / 8;

	HAL_I2C_Mem_Read(&hi2c3,0xBF,0x3C,I2C_MEMADD_SIZE_8BIT,&dado[0],1,50);
	HAL_I2C_Mem_Read(&hi2c3,0xBF,0x3D,I2C_MEMADD_SIZE_8BIT,&dado[1],1,50);

	T0_out = (dado[1] << 8) + dado[0];

	HAL_I2C_Mem_Read(&hi2c3,0xBF,0x3E,I2C_MEMADD_SIZE_8BIT,&dado[0],1,50);
	HAL_I2C_Mem_Read(&hi2c3,0xBF,0x3F,I2C_MEMADD_SIZE_8BIT,&dado[1],1,50);

	T1_out = (dado[1] << 8) + dado[0];

	HAL_I2C_Mem_Read(&hi2c3,0xBF,0x2A,I2C_MEMADD_SIZE_8BIT,&dado[0],1,50);
	HAL_I2C_Mem_Read(&hi2c3,0xBF,0x2B,I2C_MEMADD_SIZE_8BIT,&dado[1],1,50);

	T_out = (dado[1] << 8) + dado[0];

	return (((T1_degC - T0_degC) * (T_out - T0_out))/(T1_out - T0_out) + T0_degC);
}
float le_pressao(void)
{
	uint8_t dado[2];

	int pressao = 0;
	float p = 0;
	uint8_t buffer1 = 0;
	uint8_t buffer2 = 0;
	uint8_t buffer3 = 0;

	dado[0] = 0x3A;
	HAL_I2C_Mem_Write(&hi2c3,0xBA,0x10,I2C_MEMADD_SIZE_8BIT,&dado[0],1,50);
	dado[0] = 0x10;
	HAL_I2C_Mem_Write(&hi2c3,0xBA,0x11,I2C_MEMADD_SIZE_8BIT,&dado[0],1,50);

	HAL_I2C_Mem_Read(&hi2c3,0xBB,0x28,I2C_MEMADD_SIZE_8BIT,&dado[0],1,50);
	buffer1 = dado[0];

	HAL_I2C_Mem_Read(&hi2c3,0xBB,0x29,I2C_MEMADD_SIZE_8BIT,&dado[0],1,50);
	buffer2 = dado[0];

	HAL_I2C_Mem_Read(&hi2c3,0xBB,0x2A,I2C_MEMADD_SIZE_8BIT,&dado[0],1,50);
	buffer3 = dado[0];

	pressao = buffer1 + (buffer2 << 8) + (buffer3 << 16);

	pressao = pressao/4096;

	p = pressao;

	return p;
}
float le_corrente(void)
{
	float corrente = 0;

	double V = (double)c.X * 0.00073378;
	double vzinho = V - 1.5;
	corrente = (vzinho / 0.185) * 100;

	return corrente;
}
void monta_pendrive(void)
{
	if ( f_mount( &p.fatfs,"" ,0) != FR_OK )
	{
		BSP_LCD_SetFont(&Font16);
		sprintf((char*)c.vetor_print,"erro ao montar pendrive");
		BSP_LCD_DisplayStringAtLine(9,c.vetor_print);
		while(1);
	}
}
void inicializa_vetor_uint8(uint8_t vetor[], int tam)
{
  for(int i = 0; i < tam; i++)
  {
    vetor[i] = 0;
  }
}

void leitura_AD(int tempo)
{
  HAL_ADC_Start(&hadc1);
  HAL_ADC_PollForConversion(&hadc1,tempo/2);
  c.potenciometro = HAL_ADC_GetValue(&hadc1); //LEITURA DO CANAL 5
  HAL_ADC_PollForConversion(&hadc1,tempo/2);
  c.X = HAL_ADC_GetValue(&hadc1); //LEITURA DO CANAL 13 (na ordem RANK) //Pino PC3
  HAL_ADC_Stop(&hadc1);
}

void aciona_PWM(void)
{
  if(c.potenciometro > 2000 & c.potenciometro < 2095)
  {
		c.estado_atual = 0;
		if(c.estado_atual != c.estado_anterior)
		{
			BSP_LCD_Clear(LCD_COLOR_WHITE);
		}

    BSP_LCD_SetFont(&Font16);
    BSP_LCD_DisplayStringAtLine(3,(uint8_t*)"Motor Parado!");

		TIM3->CCR3 = 0;
		TIM3->CCR1 = 0;
  }
  else if(c.potenciometro >= 2095)
  {
		c.estado_atual = 1;
		if(c.estado_atual != c.estado_anterior)
		{
			BSP_LCD_Clear(LCD_COLOR_WHITE);
		}

    int pwm_percent = ((c.potenciometro-2095)*100)/2000;
    sprintf((char*)c.vetor_print,"Motor direita: %03d%%",pwm_percent);
    BSP_LCD_SetFont(&Font16);
    BSP_LCD_DisplayStringAtLine(3,c.vetor_print);

		TIM3->CCR3 = pwm_percent;
		TIM3->CCR1 = 0;
  }
  else if(c.potenciometro <= 2000)
  {
		c.estado_atual = 2;
		if(c.estado_atual != c.estado_anterior)
		{
			BSP_LCD_Clear(LCD_COLOR_WHITE);
		}

    int pwm_percent = ((2000-c.potenciometro)*100)/2000;
    sprintf((char*)c.vetor_print,"Motor esquerda: %03d%%", pwm_percent);
    BSP_LCD_SetFont(&Font16);
    BSP_LCD_DisplayStringAtLine(3,c.vetor_print);

		TIM3->CCR3 = 0;
		TIM3->CCR1 = pwm_percent;
  }

	c.estado_anterior = c.estado_atual;
}

void renderiza_RTC(void)
{
  HAL_RTC_GetTime(&hrtc, &c.sTime, FORMAT_BIN);
  HAL_RTC_GetDate(&hrtc, &c.sDate, FORMAT_BIN);

  BSP_LCD_SetFont(&Font16);
  sprintf((char*)c.vetor_print,"%02d:%02d:%02d",c.sTime.Hours,c.sTime.Minutes,c.sTime.Seconds);
  BSP_LCD_DisplayStringAtLine(1,c.vetor_print);

	sprintf((char*)c.vetor_print,"%02d/%02d/%02d",c.sDate.Date,c.sDate.Month,c.sDate.Year);
  BSP_LCD_DisplayStringAtLine(2,c.vetor_print);
}

void renderiza_sensores(void)
{
  c.umidade = le_umidade();
  c.temperatura = le_temperatura();
	c.pressao = le_pressao();
	c.corrente = le_corrente();

  BSP_LCD_SetFont(&Font16);
  sprintf((char*)c.vetor_print,"Umidade: %2.0f [%%]",c.umidade);
  BSP_LCD_DisplayStringAtLine(6,c.vetor_print);

  BSP_LCD_SetFont(&Font16);
  sprintf((char*)c.vetor_print,"Temp: %2.0f [C]",c.temperatura);
  BSP_LCD_DisplayStringAtLine(7,c.vetor_print);

	BSP_LCD_SetFont(&Font16);
  sprintf((char*)c.vetor_print,"Pressao: %4.0f [hPA]",c.pressao);
  BSP_LCD_DisplayStringAtLine(8,c.vetor_print);

	BSP_LCD_SetFont(&Font16);
  sprintf((char*)c.vetor_print,"Corrente: %4.0f [mA]",c.corrente);
  BSP_LCD_DisplayStringAtLine(9,c.vetor_print);

}

void configura_hora(void)
{
	c.sTime.Hours = (c.dadoRX[0] - 0x30)*10 + (c.dadoRX[1] - 0x30);
	c.sTime.Minutes = (c.dadoRX[3] - 0x30)*10 + (c.dadoRX[4] - 0x30);
	c.sTime.Seconds = (c.dadoRX[6] - 0x30)*10 + (c.dadoRX[7] - 0x30);

	c.sDate.Date = (c.dadoRX[9] - 0x30)*10 + (c.dadoRX[10] - 0x30);
	c.sDate.Month = (c.dadoRX[12] - 0x30)*10 + (c.dadoRX[13] - 0x30);
	c.sDate.Year = (c.dadoRX[15] - 0x30)*10 + (c.dadoRX[16] - 0x30);

	HAL_RTC_SetDate(&hrtc, &c.sDate, FORMAT_BIN);
  HAL_RTC_SetTime(&hrtc, &c.sTime, FORMAT_BIN);
}

void inicializa_display(void)
{
  BSP_LCD_Init();
	BSP_LCD_LayerDefaultInit(LCD_BACKGROUND_LAYER,LCD_FRAME_BUFFER);
	BSP_LCD_LayerDefaultInit(LCD_FOREGROUND_LAYER,LCD_FRAME_BUFFER);
	BSP_LCD_SelectLayer(LCD_FOREGROUND_LAYER);
	BSP_LCD_DisplayOn();
	BSP_LCD_Clear(LCD_COLOR_WHITE);
	BSP_LCD_SetTextColor(LCD_COLOR_RED);
	BSP_LCD_SetFont(&Font16);
	BSP_TS_Init(240, 320);
}

void pendrive(void)
{
	static int flag = 0;
	HAL_GPIO_TogglePin(GPIOG,1<<14);

	while(flag == 0) // abre o arquivo para escrita na primeira vez e deixa aberto
	{
		MX_USB_HOST_Process();
		if(Appli_state==APPLICATION_READY)
		{
			if(f_open(&p.fp,p.filename,FA_CREATE_ALWAYS | FA_WRITE)!=FR_OK)
			{
				BSP_LCD_SetFont(&Font16);
				sprintf((char*)c.vetor_print,"erro ao abrir arquivo");
				BSP_LCD_DisplayStringAtLine(9,c.vetor_print);
				while(1);
			}
			else
			{
				flag=1;
				//sprintf((char*)p.buffer,"i,temp,umid,press,amps,hora,min,seg,dia,mes,ano\n");
				//f_write(&p.fp,p.buffer,strlen((char*)p.buffer),&p.ret);
			}
		}
	}

	// configura buffer
	HAL_RTC_GetTime(&hrtc, &c.sTime, FORMAT_BIN);
  HAL_RTC_GetDate(&hrtc, &c.sDate, FORMAT_BIN);
	sprintf((char*)p.buffer,"%2d,%2.0f,%2.0f,%3.0f,%4.0f,%2d,%2d,%2d,%2d,%2d,%2d\n",c.indice,c.temperatura,c.umidade,c.pressao,c.corrente,c.sTime.Hours,
																																		c.sTime.Minutes,c.sTime.Seconds,c.sDate.Date,c.sDate.Month,c.sDate.Year);
	c.indice++;
	//

	if(f_write(&p.fp,p.buffer,strlen((char*)p.buffer),&p.ret)!=FR_OK) // vai escrevendo atИ pressionar o botao azul
	{
				BSP_LCD_SetFont(&Font16);
				sprintf((char*)c.vetor_print,"erro ao escrever no arquivo");
				BSP_LCD_DisplayStringAtLine(9,c.vetor_print);
				while(1);
	}

	if(HAL_GPIO_ReadPin(GPIOA,1)==1) // quando pressiona botao azul para de gravar e fecha o
	{
		f_close(&p.fp);
		GPIOG->BSRR=1<<13;
	}

}
/* USER CODE END 4 */

void Error_Handler(void)
{
}

/************************ (C) COPYRIGHT STMicroelectronics *****END OF FILE****/
